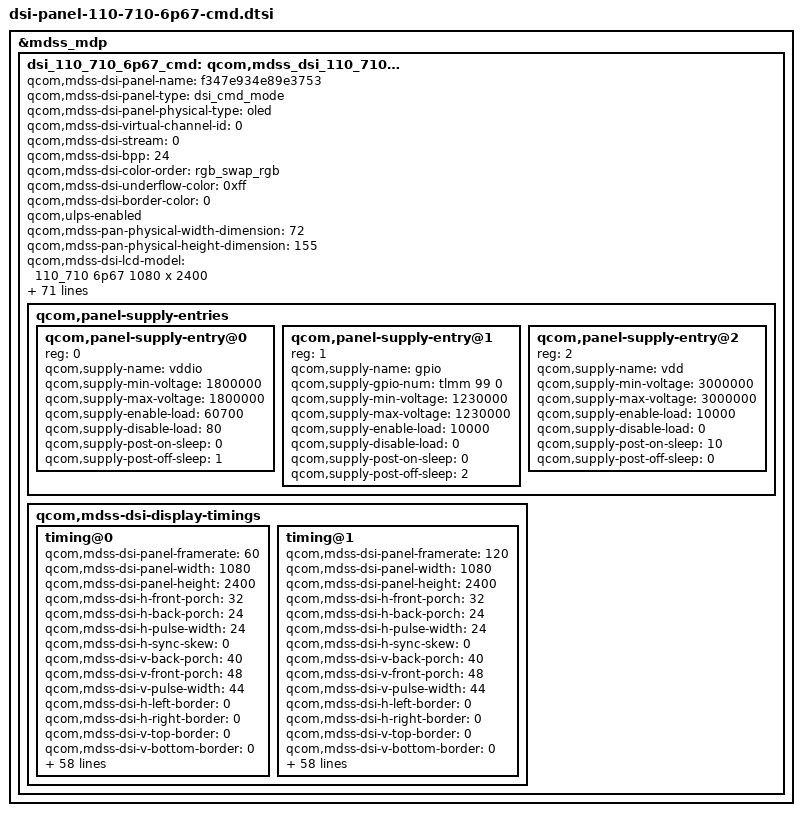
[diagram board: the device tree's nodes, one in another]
&mdss_mdp {
	dsi_110_710_6p67_cmd: qcom,mdss_dsi_110_710_6p67_cmd {
		qcom,mdss-dsi-panel-name = "f347e934e89e3753";
		qcom,mdss-dsi-panel-type = "dsi_cmd_mode";
		qcom,mdss-dsi-panel-physical-type = "oled";
		qcom,mdss-dsi-virtual-channel-id = <0>;
		qcom,mdss-dsi-stream = <0>;
		qcom,mdss-dsi-bpp = <24>;
		qcom,mdss-dsi-color-order = "rgb_swap_rgb";
		qcom,mdss-dsi-underflow-color = <0xff>;
		qcom,mdss-dsi-border-color = <0>;
		qcom,ulps-enabled;
		qcom,mdss-pan-physical-width-dimension = <72>;
		qcom,mdss-pan-physical-height-dimension = <155>;
		qcom,mdss-dsi-lcd-model = "110_710 6p67 1080 x 2400";

		/* mipi dsi setting */
		qcom,dsi-ctrl-num = <0>;
		qcom,dsi-phy-num = <0>;
		qcom,dsi-sec-ctrl-num = <1>;
		qcom,dsi-sec-phy-num = <1>;
		qcom,mdss-dsi-traffic-mode = "non_burst_sync_event";
		qcom,mdss-dsi-lane-map = "lane_map_0123";
		qcom,mdss-dsi-bllp-eof-power-mode;
		qcom,mdss-dsi-bllp-power-mode;
		qcom,mdss-dsi-lane-0-state;
		qcom,mdss-dsi-lane-1-state;
		qcom,mdss-dsi-lane-2-state;
		qcom,mdss-dsi-lane-3-state;
		qcom,mdss-dsi-dma-trigger = "trigger_sw";
		qcom,mdss-dsi-mdp-trigger = "none";
		qcom,dsi-select-clocks = "mux_byte_clk0", "mux_pixel_clk0";
		qcom,dsi-select-sec-clocks = "mux_byte_clk1", "mux_pixel_clk1";

		/* TE setting */
		qcom,mdss-dsi-te-pin-select = <1>;
		qcom,mdss-dsi-wr-mem-start = <0x2c>;
		qcom,mdss-dsi-wr-mem-continue = <0x3c>;
		qcom,mdss-dsi-te-dcs-command = <1>;
		qcom,mdss-dsi-te-check-enable;
		qcom,mdss-dsi-te-using-te-pin;

		/* hdr setting */
		qcom,mdss-dsi-panel-hdr-enabled;
		qcom,mdss-dsi-panel-hdr-color-primaries = <14500 15500 32000
			17000 15500 30000 8000 3000>;
		qcom,mdss-dsi-panel-peak-brightness = <4200000>;
		qcom,mdss-dsi-panel-blackness-level = <3230>;

		/* hbm enable */
		qcom,mdss-dsi-panel-hbm-enabled;
		/* hbm delay threshold */
		qcom,mdss-dsi-hbm-left-delaythr = <10000>;
		qcom,mdss-dsi-hbm-right-delaythr = <11500>;

		/* gpio setting */
		qcom,dsi-panel-gpio-address = <0x0F100000 0x1000>;
		qcom,dsi-panel-gpio-pins = <44 99>;
		qcom,dsi-panel-gpio-names = "reset-gpio", "vdd-gpio";

		/* esd check setting */
		qcom,mdss-dsi-panel-status-check-mode = "reg_read";
		qcom,mdss-dsi-panel-status-command = [
			06 01 00 01 00 00 01 0a
		];
		qcom,mdss-dsi-panel-status-command-state = "dsi_lp_mode";
		qcom,mdss-dsi-panel-status-value = <0x9c>;
		qcom,mdss-dsi-panel-status-read-length = <1>;
		qcom,esd-check-enabled;

		/* pcd detect*/
		qcom,mdss-dsi-panel-lcd-check-pcd-support;
		qcom,mdss-dsi-panel-lcd-pcd_value_compare_mode = <1>;
		qcom,mdss-dsi-panel-lcd-pcd_mask = <0xff>;
		qcom,mdss-dsi-panel-lcd-pcd_det_num = <1>;
		qcom,mdss-dsi-panel-lcd-check-pcd-expect_vals = <0xFF>;

		/* check reg */
		qcom,mdss-dsi-panel-lcd-check-reg-enabled;
		qcom,mdss-dsi-panel-lcd-check-reg-expect_vals = <0x9C>;

		/* oem info */
		qcom,mdss-dsi-panel-oem-info-enabled;
		qcom,mdss-dsi-panel-oem-2d-barcode-enabled;
		qcom,mdss-dsi-panel-oem-sn-enabled;

		/* backlight setting */
		qcom,mdss-dsi-bl-pmic-control-type = "bl_ctrl_dcs";
		qcom,mdss-dsi-bl-min-level = <3>;
		qcom,mdss-dsi-bl-max-level = <4095>;
		qcom,mdss-brightness-max-level = <4095>;
		qcom,mdss-dsi-bl-inverted-dbv;
		qcom,mdss-dsi-bl-max-nit = <1000>;

		/* dfps setting */
		qcom,dsi-fps-list = <60 120>;

		/* power on/off timing setting */
		qcom,platform-reset-gpio = <&tlmm 44 0>;
		qcom,mdss-dsi-reset-sequence = <1 1>, <0 1>, <1 10>;
		qcom,mdss-dsi-reset-pre-off-sleep = <2>;
		qcom,mdss-dsi-panel-reset-in-lp11;
		qcom,panel-supply-entries {
			qcom,panel-supply-entry@0 {
				reg = <0>;
				qcom,supply-name = "vddio";
				qcom,supply-min-voltage = <1800000>;
				qcom,supply-max-voltage = <1800000>;
				qcom,supply-enable-load = <60700>;
				qcom,supply-disable-load = <80>;
				qcom,supply-post-on-sleep = <0>;
				qcom,supply-post-off-sleep = <1>;
			};
			qcom,panel-supply-entry@1 {
				reg = <1>;
				//qcom,supply-name = "extvdd";
				qcom,supply-name = "gpio";
				qcom,supply-gpio-num = <&tlmm 99 0>;
				qcom,supply-min-voltage = <1230000>;
				qcom,supply-max-voltage = <1230000>;
				qcom,supply-enable-load = <10000>;
				qcom,supply-disable-load = <0>;
				qcom,supply-post-on-sleep = <0>;
				qcom,supply-post-off-sleep = <2>;
			};
			qcom,panel-supply-entry@2 {
				reg = <2>;
				qcom,supply-name = "vdd";
				qcom,supply-min-voltage = <3000000>;
				qcom,supply-max-voltage = <3000000>;
				qcom,supply-enable-load = <10000>;
				qcom,supply-disable-load = <0>;
				qcom,supply-post-on-sleep = <10>;
				qcom,supply-post-off-sleep = <0>;
			};
		};
		/* display timing0 */
		qcom,mdss-dsi-display-timings {
			timing@0 {
				qcom,mdss-dsi-panel-framerate = <60>;
				qcom,mdss-dsi-panel-width = <1080>;
				qcom,mdss-dsi-panel-height = <2400>;
				qcom,mdss-dsi-h-front-porch = <32>;
				qcom,mdss-dsi-h-back-porch = <24>;
				qcom,mdss-dsi-h-pulse-width = <24>;
				qcom,mdss-dsi-h-sync-skew = <0>;
				qcom,mdss-dsi-v-back-porch = <40>;
				qcom,mdss-dsi-v-front-porch = <48>;
				qcom,mdss-dsi-v-pulse-width = <44>;
				qcom,mdss-dsi-h-left-border = <0>;
				qcom,mdss-dsi-h-right-border = <0>;
				qcom,mdss-dsi-v-top-border = <0>;
				qcom,mdss-dsi-v-bottom-border = <0>;
				qcom,mdss-dsi-panel-jitter = <0x4 0x1>;

				qcom,mdss-dsi-on-command = [
					15 01 00 00 00 00 02 03 11
					39 01 00 00 00 00 15 A3 12 00 00 ab 30 80 09 60 04 38 00 3c 04 38 04 38 02 00 03 a3
					15 01 00 00 00 00 02 B0 14
					39 01 00 00 00 00 15 A3 00 20 06 b6 00 0f 00 0f 02 09 00 d9 18 00 10 f0 07 10 20 00
					15 01 00 00 00 00 02 B0 28
					39 01 00 00 00 00 15 A3 06 0f 0f 33 0e 1c 2a 38 46 54 62 69 70 77 79 7b 7d 7e 02 02
					15 01 00 00 00 00 02 B0 3C
					39 01 00 00 00 00 15 A3 22 00 2a 40 2a be 3a fc 3a fa 3a f8 3b 38 3b 78 3b b6 4b b6
					15 01 00 00 00 00 02 B0 50
					39 01 00 00 00 00 10 A3 4b f4 4b f4 6c 34 84 74 74 00 00 00 00 00 00
					39 01 00 00 00 00 07 86 00 10 80 00 00 00
					39 01 00 00 00 00 05 2A 00 00 04 37
					39 01 00 00 00 00 05 2B 00 00 09 5F
					39 01 00 00 00 00 03 43 02 01
					39 01 00 00 00 00 03 44 09 7E
					15 01 00 00 00 00 02 35 00
					15 01 00 00 00 00 02 53 00
					39 01 00 00 00 00 03 51 0D BB
					05 01 00 00 64 00 01 11
					39 01 00 00 00 00 03 F0 5A 5A
					39 01 00 00 00 00 04 E2 46 40 03
					39 01 00 00 00 00 16 B3 52 00 40 BA 01 1F 00 05 01 30 03 C7 80 00 00 00 00 00 00 00 7E
					05 01 00 00 14 00 01 29
				];

				qcom,mdss-dsi-off-command = [
					39 01 00 00 00 00 02 90 00
					05 01 00 00 14 00 01 28
					39 01 00 00 00 00 03 F0 5A 5A
					15 01 00 00 00 00 02 B0 02
					39 01 00 00 00 00 02 C0 52
					39 01 00 00 14 00 03 AA 01 4F
					39 01 00 00 00 00 03 AA 00 00
					05 01 00 00 50 00 01 10
				];

				qcom,mdss-dsi-fp-hbm-enable-commands = [
					39 01 00 00 00 00 03 51 0F FF
				];

				qcom,mdss-dsi-lhbm-enable-commands = [
					15 00 00 00 00 00 02 2F 02
					05 01 00 00 00 00 01 85
				];

				qcom,mdss-dsi-lhbm-disable-commands = [
					05 00 00 00 00 00 01 86
					15 01 00 00 00 00 02 2F 01
				];

				qcom,mdss-dsi-timing-switch-command = [
					39 01 00 00 0A 00 07 86 00 10 80 00 00 00
				];

				qcom,mdss-dsi-lp1-command = [
					39 01 00 00 00 00 03 90 01 00
				];

				qcom,mdss-dsi-nolp-command = [
					39 01 00 00 00 00 03 51 00 00
					39 01 00 00 00 00 03 90 00 00
					39 01 00 00 00 00 07 86 00 10 80 00 00 00
					39 01 00 00 1E 00 03 51 00 00
				];

				qcom,mdss-dsi-alpm-low-light-commands = [
					39 01 00 00 00 00 03 51 01 64
				];

				qcom,mdss-dsi-alpm-middle-light-commands = [
					39 01 00 00 00 00 03 51 07 5F
				];

				qcom,mdss-dsi-alpm-high-light-commands = [
					39 01 00 00 00 00 03 51 0F FE
				];

				qcom,mdss-dsi-panel-lcd-check-reg-commands = [
					06 01 00 01 00 00 01 0A
				];

				qcom,mdss-dsi-oeminfo-read-commands = [
					39 01 00 00 00 00 03 F0 5A 5A
					39 01 00 00 00 00 02 B0 2A
					06 01 00 00 01 00 08 BA 00 00 00 00 00 00 00
					39 01 00 00 00 00 02 B0 34
					06 01 00 00 01 00 08 BA 00 00 00 00 00 00 00
					39 01 00 00 00 00 02 B0 3C
					06 01 00 00 01 00 08 BA 00 00 00 00 00 00 00
					];

				qcom,mdss-dsi-lcd-pcd-check-open-commands = [
					39 01 00 00 00 00 03 F0 5A 5A
					39 01 00 00 0A 00 05 F8 05 02 3B 00
				];

				qcom,mdss-dsi-lcd-pcd-check-reg-commands = [
					06 01 00 00 00 00 01 CF
				];

				qcom,mdss-dsi-lcd-pcd-check-close-commands = [
					39 01 00 00 00 00 05 F8 04 02 3B 00
				];

				qcom,mdss-dsi-on-command-state = "dsi_lp_mode";
				qcom,mdss-dsi-off-command-state = "dsi_hs_mode";
				qcom,mdss-dsi-panel-lcd-check-reg-commands-state =
					"dsi_lp_mode";
				qcom,mdss-dsi-oeminfo-read-commands-state =
					"dsi_lp_mode";
				qcom,mdss-dsi-lcd-pcd-check-open-commands-state =
					"dsi_lp_mode";
				qcom,mdss-dsi-lcd-pcd-check-reg-commands-state =
					"dsi_lp_mode";
				qcom,mdss-dsi-lcd-pcd-check-close-commands-state =
					"dsi_lp_mode";

				qcom,mdss-dsi-h-sync-pulse = <0>;
				qcom,compression-mode = "dsc";
				qcom,mdss-dsc-version = <0x12>;
				qcom,mdss-dsc-slice-height = <60>;
				qcom,mdss-dsc-slice-width = <1080>;
				qcom,mdss-dsc-slice-per-pkt = <1>;
				qcom,mdss-dsc-bit-per-component = <10>;
				qcom,mdss-dsc-bit-per-pixel = <8>;
				qcom,mdss-dsc-block-prediction-enable;
				qcom,mdss-dsi-panel-phy-timings = [00 10 04 04 12 1E 04
						04 04 03 02 04 0E 09];
				qcom,display-topology = <1 1 1>;
				qcom,default-topology-index = <0>;
			};
			timing@1 {
				qcom,mdss-dsi-panel-framerate = <120>;
				qcom,mdss-dsi-panel-width = <1080>;
				qcom,mdss-dsi-panel-height = <2400>;
				qcom,mdss-dsi-h-front-porch = <32>;
				qcom,mdss-dsi-h-back-porch = <24>;
				qcom,mdss-dsi-h-pulse-width = <24>;
				qcom,mdss-dsi-h-sync-skew = <0>;
				qcom,mdss-dsi-v-back-porch = <40>;
				qcom,mdss-dsi-v-front-porch = <48>;
				qcom,mdss-dsi-v-pulse-width = <44>;
				qcom,mdss-dsi-h-left-border = <0>;
				qcom,mdss-dsi-h-right-border = <0>;
				qcom,mdss-dsi-v-top-border = <0>;
				qcom,mdss-dsi-v-bottom-border = <0>;
				qcom,mdss-dsi-panel-jitter = <0x4 0x1>;

				qcom,mdss-dsi-on-command = [
					15 01 00 00 00 00 02 03 11
					39 01 00 00 00 00 15 A3 12 00 00 ab 30 80 09 60 04 38 00 3c 04 38 04 38 02 00 03 a3
					15 01 00 00 00 00 02 B0 14
					39 01 00 00 00 00 15 A3 00 20 06 b6 00 0f 00 0f 02 09 00 d9 18 00 10 f0 07 10 20 00
					15 01 00 00 00 00 02 B0 28
					39 01 00 00 00 00 15 A3 06 0f 0f 33 0e 1c 2a 38 46 54 62 69 70 77 79 7b 7d 7e 02 02
					15 01 00 00 00 00 02 B0 3C
					39 01 00 00 00 00 15 A3 22 00 2a 40 2a be 3a fc 3a fa 3a f8 3b 38 3b 78 3b b6 4b b6
					15 01 00 00 00 00 02 B0 50
					39 01 00 00 00 00 10 A3 4b f4 4b f4 6c 34 84 74 74 00 00 00 00 00 00
					39 01 00 00 00 00 07 86 00 10 00 00 00 00
					39 01 00 00 00 00 05 2A 00 00 04 37
					39 01 00 00 00 00 05 2B 00 00 09 5F
					39 01 00 00 00 00 03 43 02 01
					39 01 00 00 00 00 03 44 09 7E
					15 01 00 00 00 00 02 35 00
					15 01 00 00 00 00 02 53 00
					39 01 00 00 00 00 03 51 0D BB
					05 01 00 00 64 00 01 11
					39 01 00 00 00 00 03 F0 5A 5A
					39 01 00 00 00 00 04 E2 46 40 03
					39 01 00 00 00 00 16 B3 52 00 40 BA 01 1F 00 05 01 30 03 C7 80 00 00 00 00 00 00 00 7E
					05 01 00 00 14 00 01 29
				];

				qcom,mdss-dsi-off-command = [
					39 01 00 00 00 00 02 90 00
					05 01 00 00 14 00 01 28
					39 01 00 00 00 00 03 F0 5A 5A
					15 01 00 00 00 00 02 B0 02
					39 01 00 00 00 00 02 C0 52
					39 01 00 00 14 00 03 AA 01 4F
					39 01 00 00 00 00 03 AA 00 00
					05 01 00 00 50 00 01 10
				];

				qcom,mdss-dsi-fp-hbm-enable-commands = [
					39 01 00 00 00 00 03 51 0F FF
				];

				qcom,mdss-dsi-lhbm-enable-commands = [
					15 00 00 00 00 00 02 2F 04
					05 01 00 00 00 00 01 85
				];

				qcom,mdss-dsi-lhbm-disable-commands = [
					05 00 00 00 00 00 01 86
					15 01 00 00 00 00 02 2F 03
				];

				qcom,mdss-dsi-timing-switch-command = [
					39 01 00 00 00 00 07 86 00 10 00 00 00 00
				];

				qcom,mdss-dsi-lp1-command = [
					39 01 00 00 00 00 03 90 01 00
				];

				qcom,mdss-dsi-nolp-command = [
					39 01 00 00 00 00 03 51 00 00
					39 01 00 00 00 00 03 90 00 00
					39 01 00 00 00 00 07 86 00 10 00 00 00 00
					39 01 00 00 1E 00 03 51 00 00
				];

				qcom,mdss-dsi-alpm-low-light-commands = [
					39 01 00 00 00 00 03 51 01 64
				];

				qcom,mdss-dsi-alpm-middle-light-commands = [
					39 01 00 00 00 00 03 51 07 5F
				];

				qcom,mdss-dsi-alpm-high-light-commands = [
					39 01 00 00 00 00 03 51 0F FE
				];

				qcom,mdss-dsi-panel-lcd-check-reg-commands = [
					06 01 00 01 00 00 01 0A
				];

				qcom,mdss-dsi-oeminfo-read-commands = [
					39 01 00 00 00 00 03 F0 5A 5A
					39 01 00 00 00 00 02 B0 2A
					06 01 00 00 01 00 08 BA 00 00 00 00 00 00 00
					39 01 00 00 00 00 02 B0 34
					06 01 00 00 01 00 08 BA 00 00 00 00 00 00 00
					39 01 00 00 00 00 02 B0 3C
					06 01 00 00 01 00 08 BA 00 00 00 00 00 00 00
					];

				qcom,mdss-dsi-lcd-pcd-check-open-commands = [
					39 01 00 00 00 00 03 F0 5A 5A
					39 01 00 00 0A 00 05 F8 05 02 3B 00
				];

				qcom,mdss-dsi-lcd-pcd-check-reg-commands = [
					06 01 00 00 00 00 01 CF
				];

				qcom,mdss-dsi-lcd-pcd-check-close-commands = [
					39 01 00 00 00 00 05 F8 04 02 3B 00
				];

				qcom,mdss-dsi-on-command-state = "dsi_lp_mode";
				qcom,mdss-dsi-off-command-state = "dsi_hs_mode";
				qcom,mdss-dsi-panel-lcd-check-reg-commands-state =
					"dsi_lp_mode";
				qcom,mdss-dsi-oeminfo-read-commands-state =
					"dsi_lp_mode";
				qcom,mdss-dsi-lcd-pcd-check-open-commands-state =
					"dsi_lp_mode";
				qcom,mdss-dsi-lcd-pcd-check-reg-commands-state =
					"dsi_lp_mode";
				qcom,mdss-dsi-lcd-pcd-check-close-commands-state =
					"dsi_lp_mode";

				qcom,mdss-dsi-h-sync-pulse = <0>;
				qcom,compression-mode = "dsc";
				qcom,mdss-dsc-version = <0x12>;
				qcom,mdss-dsc-slice-height = <60>;
				qcom,mdss-dsc-slice-width = <1080>;
				qcom,mdss-dsc-slice-per-pkt = <1>;
				qcom,mdss-dsc-bit-per-component = <10>;
				qcom,mdss-dsc-bit-per-pixel = <8>;
				qcom,mdss-dsc-block-prediction-enable;
				qcom,mdss-dsi-panel-phy-timings = [00 1C 08 07 17 16 07
					07 07 08 02 04 19 0C];
				qcom,display-topology = <1 1 1>;
				qcom,default-topology-index = <0>;
			};
		};
	};
};
